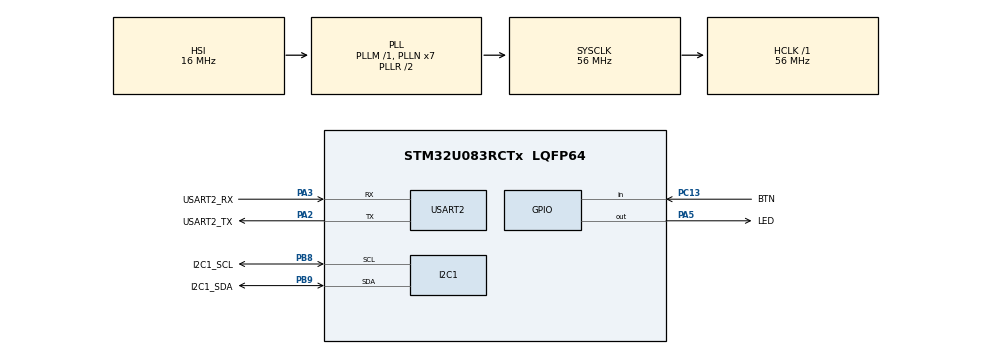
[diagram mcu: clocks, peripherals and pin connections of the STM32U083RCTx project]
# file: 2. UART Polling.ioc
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I2C1.Timing=0x10606DA4
Mcu.Family=STM32U0
Mcu.Name=STM32U083RCTx
Mcu.Package=LQFP64
NVIC.PriorityGroup=NVIC_PRIORITYGROUP_2
PA13\ (SWDIO).GPIO_Label=SWDIO
PA13\ (SWDIO).Mode=Serial_Wire
PA13\ (SWDIO).Signal=DEBUG_JTMS-SWDIO
PA14\ (SWCLK).GPIO_Label=SWCLK
PA14\ (SWCLK).Mode=Serial_Wire
PA14\ (SWCLK).Signal=DEBUG_JTCK-SWCLK
PA2.GPIO_Label=USART2_TX
PA2.Mode=Asynchronous
PA2.Signal=USART2_TX
PA3.GPIO_Label=USART2_RX
PA3.Mode=Asynchronous
PA3.Signal=USART2_RX
PA5.GPIO_Label=LED
PA5.Signal=GPIO_Output
PB8.GPIO_Label=I2C1_SCL
PB8.Mode=I2C
PB8.Signal=I2C1_SCL
PB9.GPIO_Label=I2C1_SDA
PB9.Mode=I2C
PB9.Signal=I2C1_SDA
PC13.GPIO_Label=BTN
PC13.Signal=GPIO_Input
PC14-OSC32_IN.GPIO_Label=OSC32_IN
PC14-OSC32_IN.Mode=LSE-External-Oscillator
PC14-OSC32_IN.Signal=RCC_OSC32_IN
PC15-OSC32_OUT.GPIO_Label=OSC32_OUT
PC15-OSC32_OUT.Mode=LSE-External-Oscillator
PC15-OSC32_OUT.Signal=RCC_OSC32_OUT
PF0-OSC_IN.GPIO_Label=OSC_IN
PF0-OSC_IN.Mode=HSE-External-Oscillator
PF0-OSC_IN.Signal=RCC_OSC_IN
PF1-OSC_OUT.GPIO_Label=OSC_OUT
PF1-OSC_OUT.Mode=HSE-External-Oscillator
PF1-OSC_OUT.Signal=RCC_OSC_OUT
ProjectManager.HeapSize=0x200
ProjectManager.StackSize=0x400
ProjectManager.TargetToolchain=STM32CubeIDE
RCC.ADCFreq_Value=56000000
RCC.AHBFreq_Value=56000000
RCC.CortexFreq_Value=56000000
RCC.HCLKFreq_Value=56000000
RCC.HSE_VALUE=8000000
RCC.HSI48_VALUE=48000000
RCC.HSI_VALUE=16000000
RCC.MSI_VALUE=4000000
RCC.PLLN=7
RCC.RTCClockSelection=RCC_RTCCLKSOURCE_LSE
RCC.SYSCLKFreq_VALUE=56000000
RCC.SYSCLKSource=RCC_SYSCLKSOURCE_PLLCLK
RCC.VCOOutputFreq_Value=112000000
USART2.VirtualMode-Asynchronous=VM_ASYNC
VP_PWR_VS_SECSignals.Mode=Security/Privilege
VP_RTC_VS_RTC_Activate.Mode=RTC_Enabled
board=NUCLEO-U083RC

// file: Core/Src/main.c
/* USER CODE BEGIN Header */
/**
  ******************************************************************************
  * @file           : main.c
  * @brief          : Main program body
  ******************************************************************************
  * @attention
  *
  * Copyright (c) 2025 STMicroelectronics.
  * All rights reserved.
  *
  * This software is licensed under terms that can be found in the LICENSE file
  * in the root directory of this software component.
  * If no LICENSE file comes with this software, it is provided AS-IS.
  *
  ******************************************************************************
  */
/* USER CODE END Header */
#include "main.h"
#include "i2c.h"
#include "rtc.h"
#include "usart.h"
#include "gpio.h"

/* USER CODE BEGIN Includes */
#include <stdint.h>
#include <string.h>

/* USER CODE END Includes */

void SystemClock_Config(void);

int main(void)
{

  /* MCU Configuration--------------------------------------------------------*/

  /* Reset of all peripherals, Initializes the Flash interface and the Systick. */
  HAL_Init();

  /* Configure the system clock */
  SystemClock_Config();

  /* Initialize all configured peripherals */
  MX_GPIO_Init();
  MX_I2C1_Init();
  MX_RTC_Init();
  MX_USART2_UART_Init();
  /* USER CODE BEGIN 2 */
  uint32_t pre_time = HAL_GetTick();
  /* USER CODE END 2 */

  /* Infinite loop */
  /* USER CODE BEGIN WHILE */
  while (1)
  {
    if (HAL_GetTick() - pre_time >= 500)
    {
	pre_time = HAL_GetTick();
	GPIO_PinState pin = HAL_GPIO_ReadPin(LED_GPIO_Port, LED_Pin);
	if (pin == GPIO_PIN_RESET)
	{
	    HAL_UART_Transmit(&huart2, (const uint8_t*)"LED ON\n", strlen("LED ON\n"), 100);
	}
	else
	{
	    HAL_UART_Transmit(&huart2, (const uint8_t*)"LED OFF\n", strlen("LED OFF\n"), 100);
	}
	HAL_GPIO_TogglePin(LED_GPIO_Port, LED_Pin);
    }
    /* USER CODE END WHILE */

  }
}

void SystemClock_Config(void)
{
  RCC_OscInitTypeDef RCC_OscInitStruct = {0};
  RCC_ClkInitTypeDef RCC_ClkInitStruct = {0};

  /** Configure the main internal regulator output voltage
  */
  HAL_PWREx_ControlVoltageScaling(PWR_REGULATOR_VOLTAGE_SCALE1);

  /** Configure LSE Drive Capability
  */
  HAL_PWR_EnableBkUpAccess();
  __HAL_RCC_LSEDRIVE_CONFIG(RCC_LSEDRIVE_LOW);

  /** Initializes the RCC Oscillators according to the specified parameters
  * in the RCC_OscInitTypeDef structure.
  */
  RCC_OscInitStruct.OscillatorType = RCC_OSCILLATORTYPE_HSI|RCC_OSCILLATORTYPE_LSE;
  RCC_OscInitStruct.LSEState = RCC_LSE_ON;
  RCC_OscInitStruct.HSIState = RCC_HSI_ON;
  RCC_OscInitStruct.HSICalibrationValue = RCC_HSICALIBRATION_DEFAULT;
  RCC_OscInitStruct.PLL.PLLState = RCC_PLL_ON;
  RCC_OscInitStruct.PLL.PLLSource = RCC_PLLSOURCE_HSI;
  RCC_OscInitStruct.PLL.PLLM = RCC_PLLM_DIV1;
  RCC_OscInitStruct.PLL.PLLN = 7;
  RCC_OscInitStruct.PLL.PLLP = RCC_PLLP_DIV2;
  RCC_OscInitStruct.PLL.PLLQ = RCC_PLLQ_DIV2;
  RCC_OscInitStruct.PLL.PLLR = RCC_PLLR_DIV2;
  if (HAL_RCC_OscConfig(&RCC_OscInitStruct) != HAL_OK)
  {
    Error_Handler();
  }

  /** Initializes the CPU, AHB and APB buses clocks
  */
  RCC_ClkInitStruct.ClockType = RCC_CLOCKTYPE_HCLK|RCC_CLOCKTYPE_SYSCLK
                              |RCC_CLOCKTYPE_PCLK1;
  RCC_ClkInitStruct.SYSCLKSource = RCC_SYSCLKSOURCE_PLLCLK;
  RCC_ClkInitStruct.AHBCLKDivider = RCC_SYSCLK_DIV1;
  RCC_ClkInitStruct.APB1CLKDivider = RCC_HCLK_DIV1;

  if (HAL_RCC_ClockConfig(&RCC_ClkInitStruct, FLASH_LATENCY_2) != HAL_OK)
  {
    Error_Handler();
  }
}

void Error_Handler(void)
{
  __disable_irq();
  while (1)
  {
  }
}
